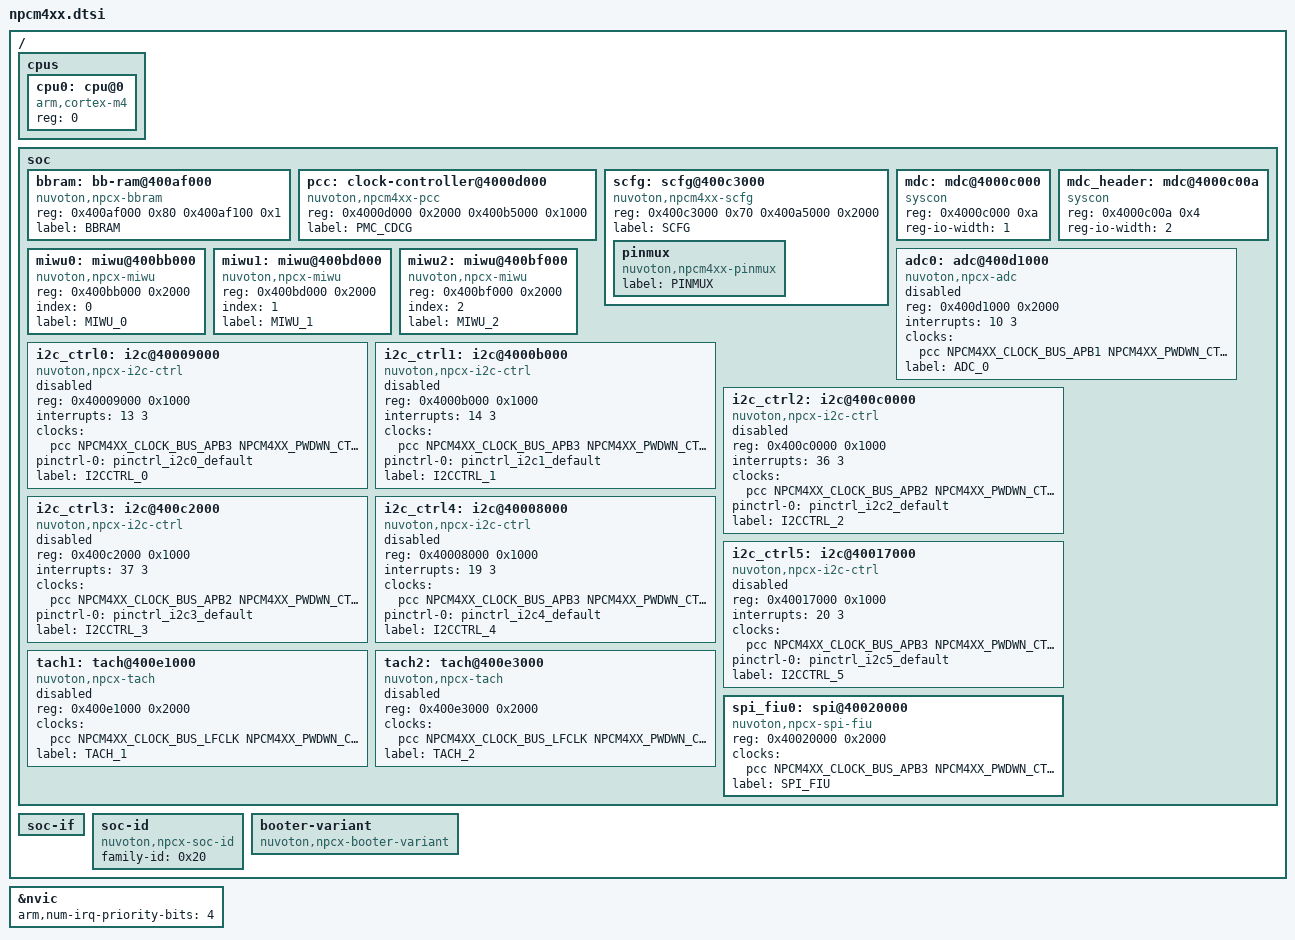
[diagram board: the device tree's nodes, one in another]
/*
 * Copyright (c) 2021 Nuvoton Technology Corporation.
 *
 * SPDX-License-Identifier: Apache-2.0
 */

#include <arm/armv7-m.dtsi>

/* Macros for device tree declarations of npcx soc family */
#include <dt-bindings/clock/npcm4xx_clock.h>
#include <dt-bindings/gpio/gpio.h>
#include <dt-bindings/i2c/i2c.h>
#include <dt-bindings/pwm/pwm.h>
#include <dt-bindings/sensor/npcx_tach.h>
#include <freq.h>

/ {
	cpus {
		#address-cells = <1>;
		#size-cells = <0>;

		cpu0: cpu@0 {
			device_type = "cpu";
			compatible = "arm,cortex-m4";
			reg = <0>;
		};
	};

	soc {
		bbram: bb-ram@400af000 {
			compatible = "nuvoton,npcx-bbram";
			reg = <0x400af000 0x80
			       0x400af100 0x1>;
			reg-names = "memory", "status";
			label = "BBRAM";
		};

		pcc: clock-controller@4000d000 {
			compatible = "nuvoton,npcm4xx-pcc";
			/* Cells for bus type, clock control reg and bit */
			#clock-cells = <3>;
			/* First reg region is Power Management Controller */
			/* Second reg region is Core Domain Clock Generator */
			reg = <0x4000d000 0x2000
			       0x400b5000 0x1000>;
			reg-names = "pmc", "cdcg";
			label = "PMC_CDCG";
		};

		scfg: scfg@400c3000 {
			compatible = "nuvoton,npcm4xx-scfg";
			/* First reg region is System Configuration Device */
			/* Second reg region is System Glue Device */
			reg = <0x400c3000 0x70
			       0x400a5000 0x2000>;
			reg-names = "scfg", "glue";
			#alt-cells = <3>;
			#lvol-cells = <4>;
			label = "SCFG";

			pinmux: pinmux {
				compatible = "nuvoton,npcm4xx-pinmux";
				label = "PINMUX";
			};
		};

		mdc: mdc@4000c000 {
			compatible = "syscon";
			reg = <0x4000c000 0xa>;
			reg-io-width = <1>;
		};

		mdc_header: mdc@4000c00a {
			compatible = "syscon";
			reg = <0x4000c00a 0x4>;
			reg-io-width = <2>;
		};

		miwu0: miwu@400bb000 {
			compatible = "nuvoton,npcx-miwu";
			reg = <0x400bb000 0x2000>;
			index = <0>;
			#miwu-cells = <2>;
			label="MIWU_0";
		};

		miwu1: miwu@400bd000 {
			compatible = "nuvoton,npcx-miwu";
			reg = <0x400bd000 0x2000>;
			index = <1>;
			#miwu-cells = <2>;
			label="MIWU_1";
		};

		miwu2: miwu@400bf000 {
			compatible = "nuvoton,npcx-miwu";
			reg = <0x400bf000 0x2000>;
			index = <2>;
			#miwu-cells = <2>;
			label="MIWU_2";
		};


		adc0: adc@400d1000 {
			compatible = "nuvoton,npcx-adc";
			#io-channel-cells = <1>;
			reg = <0x400d1000 0x2000>;
			interrupts = <10 3>;
			clocks = <&pcc NPCM4XX_CLOCK_BUS_APB1 NPCM4XX_PWDWN_CTL4 4>;
			status = "disabled";
			label = "ADC_0";
		};

		/* I2c Controllers - Do not use them as i2c node directly */
		i2c_ctrl0: i2c@40009000 {
			compatible = "nuvoton,npcx-i2c-ctrl";
			reg = <0x40009000 0x1000>;
			interrupts = <13 3>;
			clocks = <&pcc NPCM4XX_CLOCK_BUS_APB3 NPCM4XX_PWDWN_CTL3 0>;
			pinctrl-0 = <&pinctrl_i2c0_default>;
			label = "I2CCTRL_0";
			status = "disabled";
		};

		i2c_ctrl1: i2c@4000b000 {
			compatible = "nuvoton,npcx-i2c-ctrl";
			reg = <0x4000b000 0x1000>;
			interrupts = <14 3>;
			clocks = <&pcc NPCM4XX_CLOCK_BUS_APB3 NPCM4XX_PWDWN_CTL3 1>; /* may not correct */
			pinctrl-0 = <&pinctrl_i2c1_default>;
			label = "I2CCTRL_1";
			status = "disabled";
		};

		i2c_ctrl2: i2c@400c0000 {
			compatible = "nuvoton,npcx-i2c-ctrl";
			reg = <0x400c0000 0x1000>;
			interrupts = <36 3>;
			clocks = <&pcc NPCM4XX_CLOCK_BUS_APB2 NPCM4XX_PWDWN_CTL3 2>;
			pinctrl-0 = <&pinctrl_i2c2_default>;
			label = "I2CCTRL_2";
			status = "disabled";
		};

		i2c_ctrl3: i2c@400c2000 {
			compatible = "nuvoton,npcx-i2c-ctrl";
			reg = <0x400c2000 0x1000>;
			interrupts = <37 3>;
			clocks = <&pcc NPCM4XX_CLOCK_BUS_APB2 NPCM4XX_PWDWN_CTL3 3>;
			pinctrl-0 = <&pinctrl_i2c3_default>;
			label = "I2CCTRL_3";
			status = "disabled";
		};

		i2c_ctrl4: i2c@40008000 {
			compatible = "nuvoton,npcx-i2c-ctrl";
			reg = <0x40008000 0x1000>;
			interrupts = <19 3>;
			clocks = <&pcc NPCM4XX_CLOCK_BUS_APB3 NPCM4XX_PWDWN_CTL3 4>;
			pinctrl-0 = <&pinctrl_i2c4_default>;
			label = "I2CCTRL_4";
			status = "disabled";
		};

		i2c_ctrl5: i2c@40017000 {
			compatible = "nuvoton,npcx-i2c-ctrl";
			reg = <0x40017000 0x1000>;
			interrupts = <20 3>;
			clocks = <&pcc NPCM4XX_CLOCK_BUS_APB3 NPCM4XX_PWDWN_CTL3 5>;
			pinctrl-0 = <&pinctrl_i2c5_default>;
			label = "I2CCTRL_5";
			status = "disabled";
		};

		tach1: tach@400e1000 {
			compatible = "nuvoton,npcx-tach";
			reg = <0x400e1000 0x2000>;
			clocks = <&pcc NPCM4XX_CLOCK_BUS_LFCLK NPCM4XX_PWDWN_CTL1 5>;
			label = "TACH_1";
			status = "disabled";
		};

		tach2: tach@400e3000 {
			compatible = "nuvoton,npcx-tach";
			reg = <0x400e3000 0x2000>;
			clocks = <&pcc NPCM4XX_CLOCK_BUS_LFCLK NPCM4XX_PWDWN_CTL1 6>;
			label = "TACH_2";
			status = "disabled";
		};


		/* Dedicated SPI interface to access SPI flashes */
		spi_fiu0: spi@40020000 {
			compatible = "nuvoton,npcx-spi-fiu";
			#address-cells = <1>;
			#size-cells = <0>;
			reg = <0x40020000 0x2000>;
			clocks = <&pcc NPCM4XX_CLOCK_BUS_APB3 NPCM4XX_PWDWN_CTL1 2>;
			label = "SPI_FIU";
		};
	};

	soc-if {
		/* Soc specific peripheral interface phandles which don't contain
		 * 'reg' prop. Please overwrite 'status' prop. to 'okay' if you
		 * want to switch the interface from io to specific peripheral.
		 */
	};

	soc-id {
		compatible = "nuvoton,npcx-soc-id";
		family-id = <0x20>;
	};

	booter-variant {
		compatible = "nuvoton,npcx-booter-variant";
	};
};

&nvic {
	arm,num-irq-priority-bits = <4>;
};
